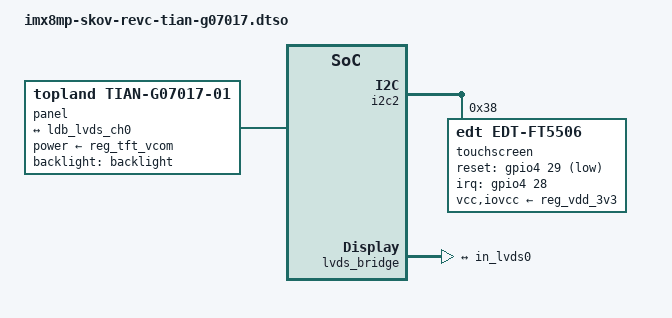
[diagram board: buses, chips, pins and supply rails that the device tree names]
// SPDX-License-Identifier: (GPL-2.0 OR MIT)

/dts-v1/;
/plugin/;

#include <dt-bindings/gpio/gpio.h>
#include <dt-bindings/interrupt-controller/irq.h>

&{/} {
	model = "SKOV IMX8MP CPU revC - TIAN G07017";
	compatible = "skov,imx8mp-skov-revc-tian-g07017", "fsl,imx8mp";

	panel {
		compatible = "topland,tian-g07017-01";
		backlight = <&backlight>;
		power-supply = <&reg_tft_vcom>;

		port {
			in_lvds0: endpoint {
				remote-endpoint = <&ldb_lvds_ch0>;
			};
		};
	};
};

&i2c2 {
	#address-cells = <1>;
	#size-cells = <0>;

	touchscreen@38 {
		compatible = "edt,edt-ft5506";
		reg = <0x38>;
		pinctrl-names = "default";
		pinctrl-0 = <&pinctrl_touchscreen>;
		interrupts-extended = <&gpio4 28 IRQ_TYPE_EDGE_FALLING>;
		reset-gpios = <&gpio4 29 GPIO_ACTIVE_LOW>;
		touchscreen-size-x = <1024>;
		touchscreen-size-y = <600>;
		vcc-supply = <&reg_vdd_3v3>;
		iovcc-supply = <&reg_vdd_3v3>;
		wakeup-source;
	};
};

&lvds_bridge {
	/* IMX8MP_VIDEO_PLL1 = IMX8MP_CLK_MEDIA_DISP2_PIX * 2 * 7 */
	assigned-clock-rates = <0>, <358400000>;

	ports {
		#address-cells = <1>;
		#size-cells = <0>;

		port@1 {
			reg = <1>;

			ldb_lvds_ch0: endpoint {
				remote-endpoint = <&in_lvds0>;
			};
		};
	};
};
